# PY32MD420xx register map
Vendor: Puya; Series: PY32M; File version: 1.0.0
CPU: CM0+ r0p1, little endian, no MPU, no FPU, 4 interrupt priority bits
Registers are 32-bit, read-write, reset 0x0 unless marked. A register's access mark holds for its fields unless they carry their own. Offsets are from the block's base; [hi:lo] are bit positions.

## SYSCFG — System configuration controller
Base 0x40010000
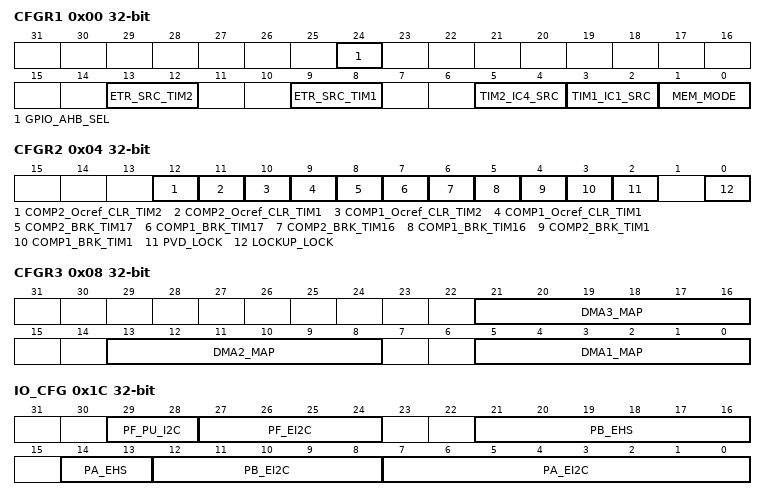
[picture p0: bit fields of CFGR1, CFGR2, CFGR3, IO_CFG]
0x00 CFGR1 — SYSCFG configuration register1
  [24] GPIO_AHB_SEL
  [13:12] ETR_SRC_TIM2
    1=0; 2=1
  [9:8] ETR_SRC_TIM1
    1=0; 2=1
  [5:4] TIM2_IC4_SRC
    1=0; 2=1
  [3:2] TIM1_IC1_SRC
    1=0; 2=1
  [1:0] MEM_MODE — Memory mapping selection bits
    1=0; 2=1
0x04 CFGR2 — SYSCFG configuration register2
  [12] COMP2_Ocref_CLR_TIM2
  [11] COMP2_Ocref_CLR_TIM1
  [10] COMP1_Ocref_CLR_TIM2
  [9] COMP1_Ocref_CLR_TIM1
  [8] COMP2_BRK_TIM17 — COMP2 is enable to input of TIM17 break
  [7] COMP1_BRK_TIM17 — COMP1 is enable to input of TIM17 break
  [6] COMP2_BRK_TIM16 — COMP2 is enable to input of TIM16 break
  [5] COMP1_BRK_TIM16 — COMP1 is enable to input of TIM16 break
  [4] COMP2_BRK_TIM1 — COMP2 is enable to input of TIM1 break
  [3] COMP1_BRK_TIM1 — COMP1 is enable to input of TIM1 break
  [2] PVD_LOCK — PVD lock enable bit
  [0] LOCKUP_LOCK — Cortex-M0+ LOCKUP bit enable bit
0x08 CFGR3 — SYSCFG configuration register3
  [all] fields
    1=0; 2=1; 4=2; 8=3; 16=4; 32=5
  [21:16] DMA3_MAP — DMA channel3 requeset selection
  [13:8] DMA2_MAP — DMA channel2 requeset selection
  [5:0] DMA1_MAP — DMA channel1 requeset selection
0x10 PA_ENS — GPIOA noise filter enable register
  [15:0] PA_ENS — Noise filter enable, active high
0x14 PB_ENS — GPIOB noise filter enable register
  [15:0] PB_ENS — Noise filter enable, active high
0x18 PF_ENS — GPIOF noise filter enable register
  [15:0] PF_ENS — Noise filter enable, active high
0x1C IO_CFG — I2C type IO configure register
  [29:28] PF_PU_I2C, [27:24] PF_EI2C, [21:16] PB_EHS, [14:13] PA_EHS, [12:8] PB_EI2C, [7:0] PA_EI2C
0x20 PA_ANA2EN — GPIOA Analog2 enable register
  [15:0] PA_ANA2EN — IO PORTA PAD_ANA2 enable
0x24 PB_ANA2EN — GPIOB Analog2 enable register
  [15:0] PB_ANA2EN — IO PORTB PAD_ANA2 enable
0x28 PF_ANA2EN — GPIOF Analog2 enable register
  [15:0] PF_ANA2EN — IO PORTF PAD_ANA2 enable

## TIM14 — General purpose timer
Base 0x40002000
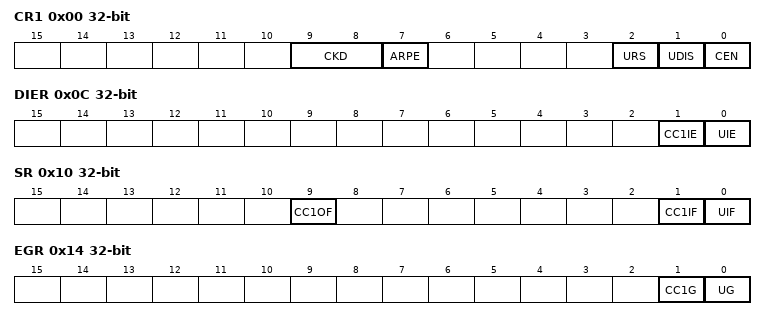
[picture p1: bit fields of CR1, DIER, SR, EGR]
0x00 CR1 — TIM14 control register1
  [9:8] CKD — Prescaler factor
    1=0; 2=1
  [7] ARPE — Auto-reload preload enable
  [2] URS — Update request source
  [1] UDIS — Update disable
  [0] CEN — Counter enable
0x0C DIER — DMA/Interrupt enable register
  [1] CC1IE — Compare/
  [0] UIE — Update interrupt enable
0x10 SR — status register
  [9] CC1OF — Compare/capture 1 flag
  [1] CC1IF — Compare/capture 1 interrupt flag
  [0] UIF — Update interrupt flag
0x14 EGR wo — event generation register
  [1] CC1G — Compare/capture1 event
  [0] UG — Update generation
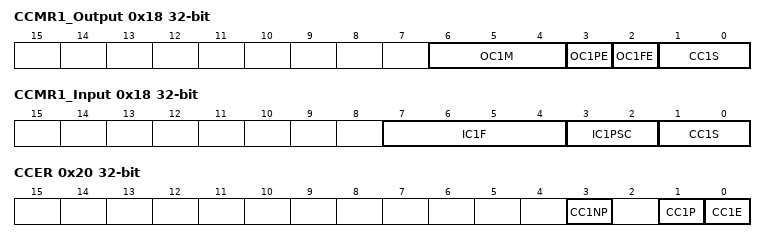
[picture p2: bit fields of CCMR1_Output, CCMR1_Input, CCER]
0x18 CCMR1_Output — capture/compare mode register (outputmode)
  [6:4] OC1M — Output Compare 1 mode
  [3] OC1PE — Output Compare 1 preload enable
  [2] OC1FE — Output Compare 1 fast enable
  [1:0] CC1S — Capture/Compare 1 selection
0x18 CCMR1_Input (alternate view of CCMR1_Output) — capture/compare mode register 1 (inputmode)
  [7:4] IC1F — Input capture 1 filter
  [3:2] IC1PSC — Input capture 1 prescaler
  [1:0] CC1S — Capture/Compare 1 selection
0x20 CCER — capture/compare enableregister
  [3] CC1NP — Capture/Compare 1 output Polarity
  [1] CC1P — Capture/Compare 1 output Polarity
  [0] CC1E — Capture/Compare 1 output enable
0x24 CNT — counter
  [15:0] CNT — counter value
0x28 PSC — prescaler
  [15:0] PSC — Prescaler value
0x2C ARR — auto-reload register
  [15:0] ARR — Auto-reload value
0x34 CCR1 — capture/compare register 1
  [15:0] CCR1 — Capture/Compare 1 value
0x50 OR — Option register
  [1:0] TI1_RMP — TIM14 channel1 input remap
    1=0; 2=1

## TIM16 — General purpose timer
Base 0x40014400
Same registers: TIM17 0x40014800
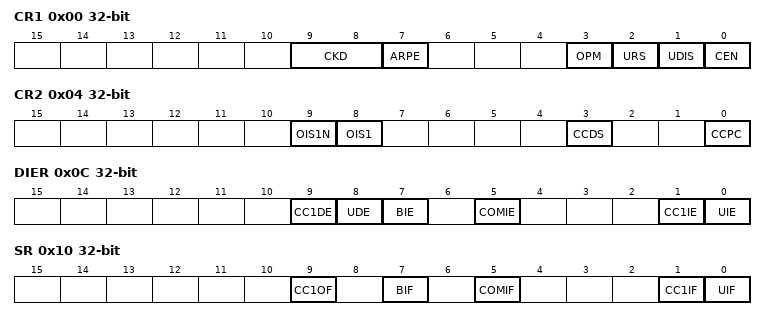
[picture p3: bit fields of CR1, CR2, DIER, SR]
0x00 CR1 — TIM16 control register1
  [9:8] CKD — Prescaler factor
    1=0; 2=1
  [7] ARPE — Auto-reload preload enable
  [3] OPM — One pulse mode
  [2] URS — Update request source
  [1] UDIS — Update disable
  [0] CEN — Counter enable
0x04 CR2 — control register 2
  [9] OIS1N — Output Idle state 1
  [8] OIS1 — Output Idle state 1
  [3] CCDS — Capture/compare DMA selection
  [0] CCPC — Capture/compare preloaded control
0x0C DIER — DMA/Interrupt enable register
  [9] CC1DE — Compare/capture DMA requeset enable
  [8] UDE — Update DMA request enable
  [7] BIE — Break interrupt enable
  [5] COMIE — Com interrupt enable
  [1] CC1IE — Capture/Compare 1 interrupt enable
  [0] UIE — Update interrupt enable
0x10 SR — status register
  [9] CC1OF — Update interrupt flag
  [7] BIF — Break interrupt flag
  [5] COMIF — Com interrupt flag
  [1] CC1IF — Capture/Compare 1 interrupt flag
  [0] UIF — Update interrupt flag
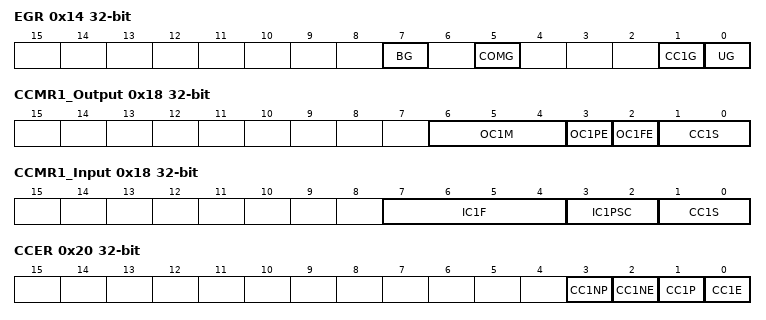
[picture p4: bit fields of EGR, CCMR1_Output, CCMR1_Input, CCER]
0x14 EGR wo — event generation register
  [7] BG — Break event generation
  [5] COMG — COM evnet generation
  [1] CC1G — Capture/Compare 1 generation
  [0] UG — Update generation
0x18 CCMR1_Output — capture/compare mode register (outputmode)
  [6:4] OC1M — Output Compare 1 mode
  [3] OC1PE — Output Compare 1 preload enable
  [2] OC1FE — Output Compare 1 fast enable
  [1:0] CC1S — Capture/Compare 1 selection
0x18 CCMR1_Input (alternate view of CCMR1_Output) — capture/compare mode register 1 (inputmode)
  [7:4] IC1F — Input capture 1 filter
  [3:2] IC1PSC — Input capture 1 prescaler
  [1:0] CC1S — Capture/Compare 1 selection
0x20 CCER — capture/compare enableregister
  [3] CC1NP — Capture/Compare 1 output Polarity
  [2] CC1NE — Capture/Compare 1 complementary output enable
  [1] CC1P — Capture/Compare 1 output Polarity
  [0] CC1E — Capture/Compare 1 output enable
0x24 CNT — counter
  [15:0] CNT — counter value
0x28 PSC — prescaler
  [15:0] PSC — Prescaler value
0x2C ARR — auto-reload register
  [15:0] ARR — Auto-reload value
0x30 RCR — repetition counter register
  [7:0] REP — Repetition counter value
0x34 CCR1 — capture/compare register 1
  [15:0] CCR1 — Capture/Compare 1 value
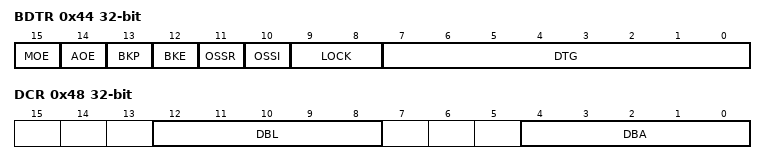
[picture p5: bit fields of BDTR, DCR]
0x44 BDTR — break and dead-time register
  [15] MOE — Main output enable
  [14] AOE — Automatic output enable
  [13] BKP — Break polarity
  [12] BKE — Break enable
  [11] OSSR — Off-state selection for Run mode
  [10] OSSI — Off-state selection for Idle mode
  [9:8] LOCK — Lock configuration
    1=0; 2=1
  [7:0] DTG — Dead-time generator setup
    1=0; 2=1; 4=2; 8=3; 16=4; 32=5; 64=6; 128=7
0x48 DCR — DMA control register
  [12:8] DBL — DMA burst length
    1=0; 2=1; 4=2; 8=3; 16=4
  [4:0] DBA — DMA base address
    1=0; 2=1; 4=2; 8=3; 16=4
0x4C DMAR — DMA address for full transfer
  [31:0] DMAB — DMA register for burst accesses

## USART1 — Universal synchronous asynchronous receivertransmitter
Base 0x40013800
Same registers: USART2 0x40004400, USART3 0x40004800
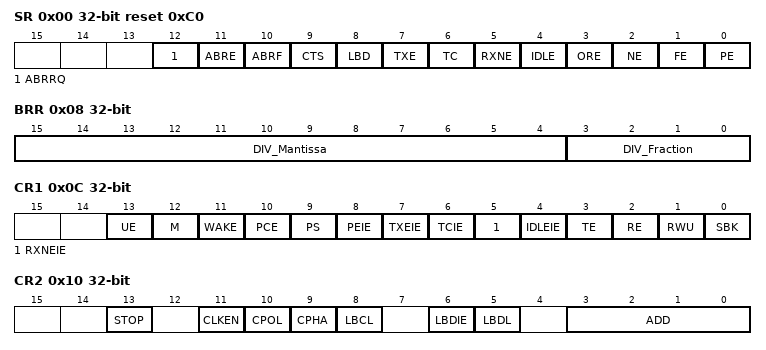
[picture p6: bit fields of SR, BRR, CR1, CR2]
0x00 SR reset 0xC0 — Status register
  [12] ABRRQ wo — Automate baudrate detection requeset
  [11] ABRE ro — Automate baudrate detection error flag
  [10] ABRF ro — Automate baudrate detection flag
  [9] CTS — CTS flag
  [8] LBD
  [7] TXE ro — Transmit data register empty
  [6] TC — Transmission complete
  [5] RXNE — Read data register not empty
  [4] IDLE ro — IDLE line detected
  [3] ORE ro — Overrun error
  [2] NE ro — Noise error flag
  [1] FE ro — Framing error
  [0] PE ro — Parity error
0x04 DR — Data register
  [8:0] DR — Data value
0x08 BRR — Baud rate register
  [15:4] DIV_Mantissa — mantissa of USARTDIV
  [3:0] DIV_Fraction — fraction of USARTDIV
0x0C CR1 — Control register 1
  [13] UE — USART enable
  [12] M — Word length
  [11] WAKE — Wakeup method
  [10] PCE — Parity control enable
  [9] PS — Parity selection
  [8] PEIE — PE interrupt enable
  [7] TXEIE — TXE interrupt enable
  [6] TCIE — Transmission complete interrupt enable
  [5] RXNEIE — RXNE interrupt enable
  [4] IDLEIE — IDLE interrupt enable
  [3] TE — Transmitter enable
  [2] RE — Receiver enable
  [1] RWU — Receiver wakeup
  [0] SBK — Send break
0x10 CR2 — Control register 2
  [13] STOP — STOP bits
  [11] CLKEN — Clock enable
  [10] CPOL — Clock polarity
  [9] CPHA — Clock phase
  [8] LBCL — Last bit clock pulse
  [6] LBDIE
  [5] LBDL
  [3:0] ADD — Address of the USART node
    1=0; 2=1; 4=2; 8=3
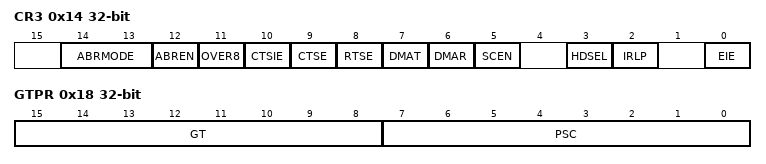
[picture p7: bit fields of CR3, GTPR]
0x14 CR3 — Control register 3
  [14:13] ABRMODE — Auto baudrate mode
    1=0; 2=1
  [12] ABREN — Auto baudrate enable
  [11] OVER8 — Oversampling mode
  [10] CTSIE — CTS interrupt enable
  [9] CTSE — CTS enable
  [8] RTSE — RTS enable
  [7] DMAT — DMA enable transmitter
  [6] DMAR — DMA enable receiver
  [5] SCEN
  [3] HDSEL — Half-duplex selection
  [2] IRLP — IrDA low-power
  [0] EIE — Error interrupt enable
0x18 GTPR
  [15:8] GT, [7:0] PSC

## WWDG — Window watchdog
Base 0x40002C00
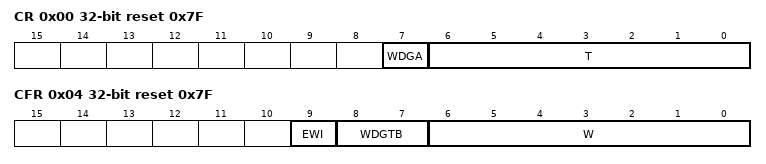
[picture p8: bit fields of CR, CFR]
0x00 CR reset 0x7F — Control register (WWDG_CR)
  [7] WDGA — Activation bit
  [6:0] T — 7-bit counter (MSB to LSB)
    1=0; 2=1; 4=2; 8=3; 16=4; 32=5; 64=6
0x04 CFR reset 0x7F — Configuration register(WWDG_CFR)
  [9] EWI — Early Wakeup Interrupt
  [8:7] WDGTB — Timer Base
    1=0; 2=1
  [6:0] W — 7-bit window value
    1=0; 2=1; 4=2; 8=3; 16=4; 32=5; 64=6
0x08 SR — Status register (WWDG_SR)
  [0] EWIF — Early Wakeup Interrupt flag
